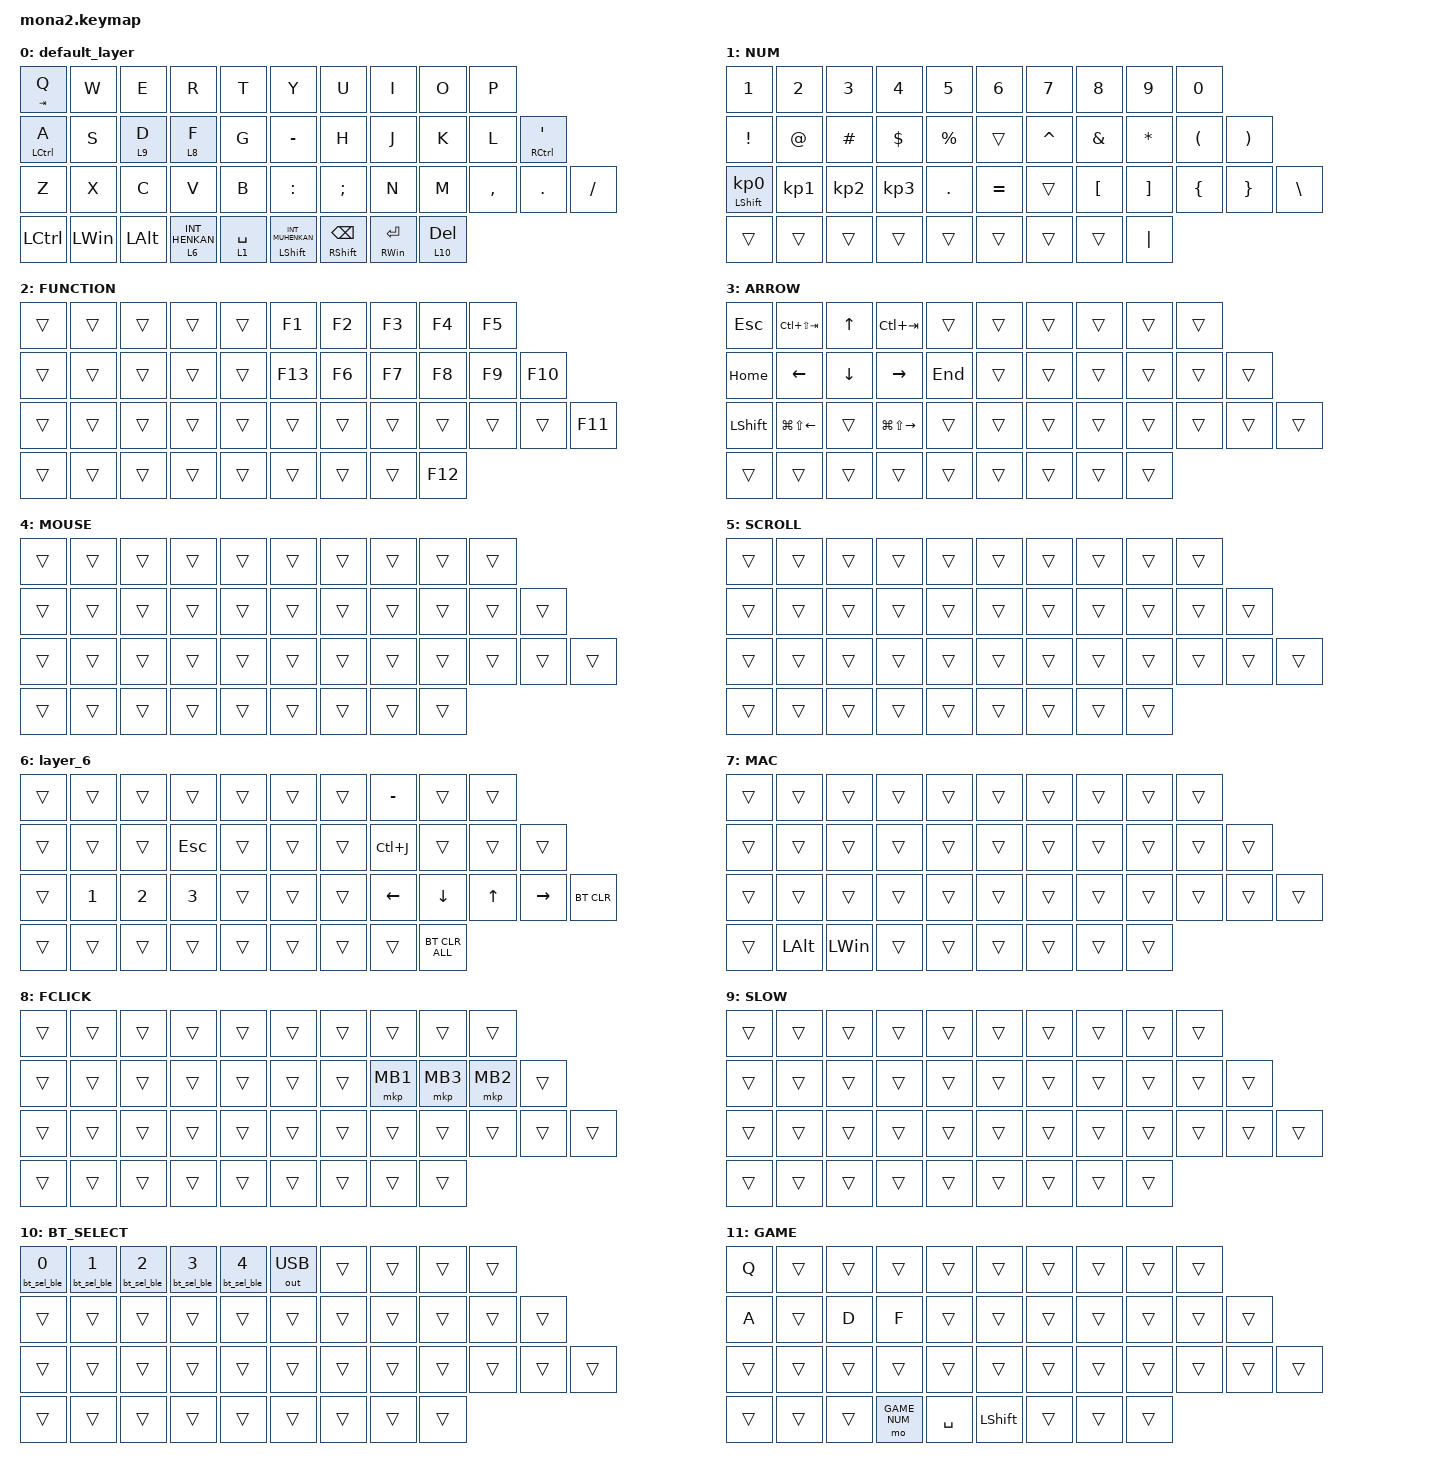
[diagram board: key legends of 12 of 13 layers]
#include <behaviors.dtsi>
#include <dt-bindings/zmk/bt.h>
#include <dt-bindings/zmk/outputs.h>
#include <dt-bindings/zmk/keys.h>
#include <dt-bindings/zmk/pointing.h>

&mt {
    flavor = "hold-preferred";
    quick-tap-ms = <0>;
};

#include <input/processors.dtsi>
#include <dt-bindings/zmk/input_transform.h>

&trackball_central_listener {
    // Overrides are evaluated in order: retain highest-layer precedence.
    bluetooth {
        layers = <10>;
        input-processors = <&zip_xy_transform INPUT_TRANSFORM_Y_INVERT>;
    };

    snipe {
        layers = <9>;
        input-processors = <&zip_xy_transform INPUT_TRANSFORM_Y_INVERT>,
                           <&zip_xy_scaler 1 2>;
    };

    scroller {
        layers = <8>;
        // Raw Y becomes wheel Y; raw X becomes horizontal wheel X.
        // This matches roBa's Y inversion plus wheel inversion.
        input-processors = <&zip_xy_to_scroll_mapper>,
                           <&zip_scroll_scaler 1 16>;
    };
};

// Game mode (toggled with G+J) is a layer above every other one, so combos
// limited to the layers below it stay off while it is on.
#define GAME 11
#define GAME_NUM 12
#define NON_GAME_LAYERS 0 1 2 3 4 5 6 7 8 9 10

/ {
    combos {
        compatible = "zmk,combos";

        // moNa2's encoder has no push switch: replace it with G+B.
        screenshot {
            bindings = <&kp LS(LG(S))>;
            key-positions = <14 25>;
            layers = <0 7>;
            timeout-ms = <50>;
        };

        tab {
            bindings = <&kp TAB>;
            key-positions = <11 12>;
            layers = <NON_GAME_LAYERS>;
        };

        shift_tab {
            bindings = <&kp LS(TAB)>;
            key-positions = <12 13>;
            layers = <NON_GAME_LAYERS>;
        };

        muhennkann {
            bindings = <&kp INT_MUHENKAN>;
            key-positions = <11 10>;
            layers = <NON_GAME_LAYERS>;
        };

        double_quotation {
            bindings = <&kp DOUBLE_QUOTES>;
            key-positions = <19 20>;
            layers = <NON_GAME_LAYERS>;
        };

        // SKK's Ctrl+J without relying on A's Ctrl hold-tap timing.
        skk_ctrl_j {
            bindings = <&kp LC(J)>;
            key-positions = <10 20>;
            layers = <NON_GAME_LAYERS>;
        };

        eq {
            bindings = <&kp EQUAL>;
            key-positions = <23 24>;
            layers = <NON_GAME_LAYERS>;
        };
        os_mode {
            bindings = <&tog 7>;
            key-positions = <12 18>;
            timeout-ms = <100>;
            slow-release;
        };

        game_mode {
            bindings = <&tog GAME>;
            key-positions = <14 17>;
            timeout-ms = <100>;
            slow-release;
        };

    };

    macros {
        // USB output takes priority over BLE while plugged in, so selecting a
        // profile alone keeps typing into the USB host: switch output too.
        bt_sel_ble: bt_sel_ble {
            compatible = "zmk,behavior-macro-one-param";
            #binding-cells = <1>;
            bindings = <&macro_param_1to2 &bt BT_SEL MACRO_PLACEHOLDER>, <&out OUT_BLE>;
        };
    };


    behaviors {
        scroll_encoder: scroll_encoder {
            compatible = "zmk,behavior-sensor-rotate";
            #sensor-binding-cells = <0>;
            tap-ms = <20>;
            bindings = <&msc MOVE_Y(-64)>, <&msc MOVE_Y(64)>;
        };

        lt_henkan: lt_henkan {
            compatible = "zmk,behavior-hold-tap";
            label = "LT_HENKAN";
            bindings = <&mo>, <&kp>;

            #binding-cells = <2>;
            tapping-term-ms = <200>;
        };

        lt_fclick: lt_fclick {
            compatible = "zmk,behavior-hold-tap";
            label = "LT_FCLICK";
            bindings = <&mo>, <&kp>;

            #binding-cells = <2>;
            flavor = "tap-preferred";
            tapping-term-ms = <200>;
            quick-tap-ms = <0>;
        };
        lt_slow: lt_slow {
            compatible = "zmk,behavior-hold-tap";
            label = "LT_SLOW";
            bindings = <&mo>, <&kp>;

            #binding-cells = <2>;
            flavor = "tap-preferred";
            tapping-term-ms = <200>;
            quick-tap-ms = <0>;
        };


        ht_q_tab: ht_q_tab {
            compatible = "zmk,behavior-hold-tap";
            label = "HT_Q_TAB";
            bindings = <&kp>, <&kp>;

            #binding-cells = <2>;
            flavor = "tap-preferred";
            tapping-term-ms = <200>;
            quick-tap-ms = <0>;
        };

        ht_a_caps: ht_a_caps {
            compatible = "zmk,behavior-hold-tap";
            label = "HT_A_CAPS";
            bindings = <&kp>, <&kp>;

            #binding-cells = <2>;
            flavor = "balanced";
            tapping-term-ms = <200>;
            quick-tap-ms = <0>;
            require-prior-idle-ms = <125>;
        };
        ht_backspace_shift: ht_backspace_shift {
            compatible = "zmk,behavior-hold-tap";
            label = "HT_BACKSPACE_SHIFT";
            bindings = <&kp>, <&kp>;

            #binding-cells = <2>;
            flavor = "hold-preferred";
            tapping-term-ms = <250>;
            quick-tap-ms = <0>;
        };
        ht_enter_right_command: ht_enter_right_command {
            compatible = "zmk,behavior-hold-tap";
            label = "HT_ENTER_RIGHT_COMMAND";
            bindings = <&kp>, <&kp>;

            #binding-cells = <2>;
            flavor = "hold-preferred";
            tapping-term-ms = <250>;
            quick-tap-ms = <0>;
        };
        ht_muhenkan_shift: ht_muhenkan_shift {
            compatible = "zmk,behavior-hold-tap";
            label = "HT_MUHENKAN_SHIFT";
            bindings = <&kp>, <&kp>;

            #binding-cells = <2>;
            flavor = "hold-preferred";
            tapping-term-ms = <250>;
            quick-tap-ms = <0>;
        };
        lt_bt_select: lt_bt_select {
            compatible = "zmk,behavior-hold-tap";
            label = "LT_BT_SELECT";
            bindings = <&mo>, <&kp>;

            #binding-cells = <2>;
            flavor = "hold-preferred";
            tapping-term-ms = <250>;
            quick-tap-ms = <0>;
        };






    };

    keymap {
        compatible = "zmk,keymap";

        default_layer {
            bindings = <
&ht_q_tab TAB Q  &kp W  &kp E  &kp R  &kp T  &kp Y  &kp U  &kp I  &kp O  &kp P
&ht_a_caps LEFT_CONTROL A  &kp S  &lt_slow 9 D  &lt_fclick 8 F  &kp G  &kp MINUS  &kp H  &kp J  &kp K  &kp L  &mt RIGHT_CONTROL SQT
&kp Z  &kp X  &kp C  &kp V  &kp B  &kp COLON  &kp SEMICOLON  &kp N  &kp M  &kp COMMA  &kp DOT  &kp SLASH
&kp LCTRL  &kp LEFT_WIN  &kp LEFT_ALT  &lt_henkan 6 INT_HENKAN  &lt 1 SPACE  &ht_muhenkan_shift LEFT_SHIFT INT_MUHENKAN  &ht_backspace_shift RIGHT_SHIFT BACKSPACE  &ht_enter_right_command RIGHT_WIN ENTER  &lt_bt_select 10 DEL
            >;

            sensor-bindings = <&scroll_encoder>;
        };

        NUM {
            bindings = <
&kp NUMBER_1  &kp NUMBER_2  &kp NUMBER_3  &kp NUMBER_4  &kp NUMBER_5  &kp NUMBER_6  &kp NUMBER_7  &kp NUMBER_8  &kp NUMBER_9  &kp NUMBER_0
&kp EXCLAMATION  &kp AT_SIGN  &kp HASH  &kp DOLLAR  &kp PERCENT  &trans  &kp CARET  &kp AMPERSAND  &kp ASTERISK  &kp LEFT_PARENTHESIS  &kp RIGHT_PARENTHESIS
&mt LEFT_SHIFT KP_NUMBER_0  &kp KP_NUMBER_1  &kp KP_NUMBER_2  &kp KP_NUMBER_3  &kp PERIOD  &kp EQUAL  &trans  &kp LEFT_BRACKET  &kp RIGHT_BRACKET  &kp LEFT_BRACE  &kp RIGHT_BRACE  &kp BACKSLASH
&trans  &trans  &trans  &trans  &trans  &trans  &trans  &trans  &kp PIPE
            >;
        };

        FUNCTION {
            bindings = <
&trans  &trans  &trans  &trans  &trans  &kp F1  &kp F2  &kp F3  &kp F4  &kp F5
&trans  &trans  &trans  &trans  &trans  &kp F13  &kp F6  &kp F7  &kp F8  &kp F9  &kp F10
&trans  &trans  &trans  &trans  &trans  &trans  &trans  &trans  &trans  &trans  &trans  &kp F11
&trans  &trans  &trans  &trans  &trans  &trans  &trans  &trans  &kp F12
            >;
        };

        ARROW {
            bindings = <
&kp ESCAPE  &kp LC(LS(TAB))  &kp UP_ARROW  &kp LC(TAB)  &trans  &trans  &trans  &trans  &trans  &trans
&kp HOME  &kp LEFT_ARROW  &kp DOWN_ARROW  &kp RIGHT_ARROW  &kp END  &trans  &trans  &trans  &trans  &trans  &trans
&kp LEFT_SHIFT  &kp LG(LS(LEFT_ARROW))  &trans  &kp LG(LS(RIGHT_ARROW))  &trans  &trans  &trans  &trans  &trans  &trans  &trans  &trans
&trans  &trans  &trans  &trans  &trans  &trans  &trans  &trans  &trans
            >;

            sensor-bindings = <&inc_dec_kp LC(PAGE_UP) LC(PAGE_DOWN)>;
        };

        MOUSE {
            bindings = <
&trans  &trans  &trans  &trans  &trans  &trans  &trans  &trans  &trans  &trans
&trans  &trans  &trans  &trans  &trans  &trans  &trans  &trans  &trans  &trans  &trans
&trans  &trans  &trans  &trans  &trans  &trans  &trans  &trans  &trans  &trans  &trans  &trans
&trans  &trans  &trans  &trans  &trans  &trans  &trans  &trans  &trans
            >;
        };

        SCROLL {
            bindings = <
&trans  &trans  &trans  &trans  &trans  &trans  &trans  &trans  &trans  &trans
&trans  &trans  &trans  &trans  &trans  &trans  &trans  &trans  &trans  &trans  &trans
&trans  &trans  &trans  &trans  &trans  &trans  &trans  &trans  &trans  &trans  &trans  &trans
&trans  &trans  &trans  &trans  &trans  &trans  &trans  &trans  &trans
            >;
        };

        layer_6 {
            bindings = <
&trans  &trans  &trans  &trans  &trans  &trans  &trans  &kp MINUS  &trans  &trans
&trans  &trans  &trans  &kp ESC  &trans  &trans  &trans  &kp LC(J)  &trans  &trans  &trans
&trans  &kp NUMBER_1  &kp NUMBER_2  &kp NUMBER_3  &trans  &trans  &trans  &kp LEFT_ARROW  &kp DOWN_ARROW  &kp UP_ARROW  &kp RIGHT_ARROW  &bt BT_CLR
&trans  &trans  &trans  &trans  &trans  &trans  &trans  &trans  &bt BT_CLR_ALL
            >;
        };

        MAC {
            bindings = <
&trans  &trans  &trans  &trans  &trans  &trans  &trans  &trans  &trans  &trans
&trans  &trans  &trans  &trans  &trans  &trans  &trans  &trans  &trans  &trans  &trans
&trans  &trans  &trans  &trans  &trans  &trans  &trans  &trans  &trans  &trans  &trans  &trans
&trans  &kp LEFT_ALT  &kp LEFT_WIN  &trans  &trans  &trans  &trans  &trans  &trans
            >;
        };
        FCLICK {
            bindings = <
&trans  &trans  &trans  &trans  &trans  &trans  &trans  &trans  &trans  &trans
&trans  &trans  &trans  &trans  &trans  &trans  &trans  &mkp MB1  &mkp MB3  &mkp MB2  &trans
&trans  &trans  &trans  &trans  &trans  &trans  &trans  &trans  &trans  &trans  &trans  &trans
&trans  &trans  &trans  &trans  &trans  &trans  &trans  &trans  &trans
            >;
        };
        SLOW {
            bindings = <
&trans  &trans  &trans  &trans  &trans  &trans  &trans  &trans  &trans  &trans
&trans  &trans  &trans  &trans  &trans  &trans  &trans  &trans  &trans  &trans  &trans
&trans  &trans  &trans  &trans  &trans  &trans  &trans  &trans  &trans  &trans  &trans  &trans
&trans  &trans  &trans  &trans  &trans  &trans  &trans  &trans  &trans
            >;
        };
        BT_SELECT {
            bindings = <
&bt_sel_ble 0  &bt_sel_ble 1  &bt_sel_ble 2  &bt_sel_ble 3  &bt_sel_ble 4  &out OUT_USB  &trans  &trans  &trans  &trans
&trans  &trans  &trans  &trans  &trans  &trans  &trans  &trans  &trans  &trans  &trans
&trans  &trans  &trans  &trans  &trans  &trans  &trans  &trans  &trans  &trans  &trans  &trans
&trans  &trans  &trans  &trans  &trans  &trans  &trans  &trans  &trans
            >;
        };

        // Plain keys where a hold-tap would delay or swallow game input:
        // Q (Tab), A (Ctrl), D (SLOW), F (FCLICK), Space (NUM), and the left
        // thumb Shift (Muhenkan). Henkan opens GAME_NUM instead of layer 6.
        GAME {
            bindings = <
&kp Q  &trans  &trans  &trans  &trans  &trans  &trans  &trans  &trans  &trans
&kp A  &trans  &kp D  &kp F  &trans  &trans  &trans  &trans  &trans  &trans  &trans
&trans  &trans  &trans  &trans  &trans  &trans  &trans  &trans  &trans  &trans  &trans  &trans
&trans  &trans  &trans  &mo GAME_NUM  &kp SPACE  &kp LEFT_SHIFT  &trans  &trans  &trans
            >;
        };

        // Held Henkan in game mode: NUM's number row, and Esc on F as in layer 6.
        GAME_NUM {
            bindings = <
&kp NUMBER_1  &kp NUMBER_2  &kp NUMBER_3  &kp NUMBER_4  &kp NUMBER_5  &kp NUMBER_6  &kp NUMBER_7  &kp NUMBER_8  &kp NUMBER_9  &kp NUMBER_0
&trans  &trans  &trans  &kp ESC  &trans  &trans  &trans  &trans  &trans  &trans  &trans
&trans  &trans  &trans  &trans  &trans  &trans  &trans  &trans  &trans  &trans  &trans  &trans
&trans  &trans  &trans  &trans  &trans  &trans  &trans  &trans  &trans
            >;
        };
    };
};
